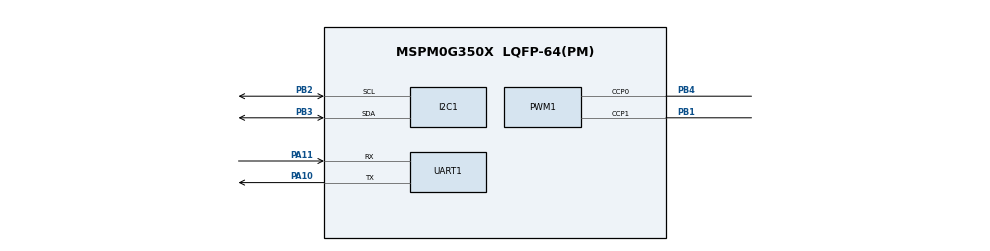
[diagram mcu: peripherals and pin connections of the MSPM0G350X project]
/**
 * @cliArgs --device "MSPM0G350X" --package "LQFP-64(PM)" --part "Default" --product "mspm0_sdk@2.01.00.03"
 * @versions {"tool":"1.20.0+3587"}
 */

/**
 * Import the modules used in this configuration.
 */
const GPIO   = scripting.addModule("/ti/driverlib/GPIO", {}, false);
const GPIO1  = GPIO.addInstance();
const GPIO2  = GPIO.addInstance();
const GPIO3  = GPIO.addInstance();
const GPIO4  = GPIO.addInstance();
const GPIO5  = GPIO.addInstance();
const I2C    = scripting.addModule("/ti/driverlib/I2C", {}, false);
const I2C1   = I2C.addInstance();
const PWM    = scripting.addModule("/ti/driverlib/PWM", {}, false);
const PWM1   = PWM.addInstance();
const SYSCTL = scripting.addModule("/ti/driverlib/SYSCTL");
const TIMER  = scripting.addModule("/ti/driverlib/TIMER", {}, false);
const TIMER1 = TIMER.addInstance();
const UART   = scripting.addModule("/ti/driverlib/UART", {}, false);
const UART1  = UART.addInstance();
const UART2  = UART.addInstance();

/**
 * Write custom configuration values to the imported modules.
 */
const divider6       = system.clockTree["PLL_CLK2X_DIV"];
divider6.divideValue = 4;

const divider7       = system.clockTree["PLL_PDIV"];
divider7.divideValue = 2;

const divider9       = system.clockTree["UDIV"];
divider9.divideValue = 2;

const multiplier2         = system.clockTree["PLL_QDIV"];
multiplier2.multiplyValue = 10;

const mux8       = system.clockTree["HSCLKMUX"];
mux8.inputSelect = "HSCLKMUX_SYSPLL2X";

GPIO1.$name                          = "GRP_RIGHT_AIN";
GPIO1.associatedPins.create(2);
GPIO1.associatedPins[0].assignedPin  = "12";
GPIO1.associatedPins[0].assignedPort = "PORTB";
GPIO1.associatedPins[0].$name        = "RIGHT_AIN1";
GPIO1.associatedPins[1].assignedPort = "PORTB";
GPIO1.associatedPins[1].assignedPin  = "17";
GPIO1.associatedPins[1].$name        = "RIGHT_AIN2";

const Board = scripting.addModule("/ti/driverlib/Board", {}, false);

GPIO2.$name                          = "GRP_LEFT_BIN";
GPIO2.associatedPins.create(2);
GPIO2.associatedPins[0].assignedPort = "PORTA";
GPIO2.associatedPins[0].assignedPin  = "28";
GPIO2.associatedPins[0].$name        = "LEFT_BIN1";
GPIO2.associatedPins[1].assignedPort = "PORTA";
GPIO2.associatedPins[1].assignedPin  = "31";
GPIO2.associatedPins[1].$name        = "LEFT_BIN2";

GPIO3.$name                          = "GRP_ENCODER_RIGHT";
GPIO3.associatedPins.create(2);
GPIO3.associatedPins[0].assignedPort = "PORTB";
GPIO3.associatedPins[0].assignedPin  = "20";
GPIO3.associatedPins[0].direction    = "INPUT";
GPIO3.associatedPins[0].interruptEn  = true;
GPIO3.associatedPins[0].polarity     = "RISE_FALL";
GPIO3.associatedPins[0].$name        = "RIGHT_A";
GPIO3.associatedPins[1].direction    = "INPUT";
GPIO3.associatedPins[1].assignedPort = "PORTB";
GPIO3.associatedPins[1].assignedPin  = "13";
GPIO3.associatedPins[1].$name        = "RIGHT_B";

GPIO4.$name                          = "GRP_ENCODER_LEFT";
GPIO4.associatedPins.create(2);
GPIO4.associatedPins[0].assignedPort = "PORTB";
GPIO4.associatedPins[0].direction    = "INPUT";
GPIO4.associatedPins[0].assignedPin  = "15";
GPIO4.associatedPins[0].interruptEn  = true;
GPIO4.associatedPins[0].polarity     = "RISE_FALL";
GPIO4.associatedPins[0].$name        = "LEFT_A";
GPIO4.associatedPins[1].direction    = "INPUT";
GPIO4.associatedPins[1].assignedPort = "PORTB";
GPIO4.associatedPins[1].assignedPin  = "8";
GPIO4.associatedPins[1].$name        = "LEFT_B";

GPIO5.$name                          = "GPIO_OLED";
GPIO5.associatedPins.create(2);
GPIO5.associatedPins[0].$name        = "PIN_SCL";
GPIO5.associatedPins[0].assignedPort = "PORTA";
GPIO5.associatedPins[0].assignedPin  = "12";
GPIO5.associatedPins[1].$name        = "PIN_SDA";
GPIO5.associatedPins[1].assignedPort = "PORTA";
GPIO5.associatedPins[1].assignedPin  = "13";

I2C1.$name                             = "I2C_MPU6050";
I2C1.basicEnableController             = true;
I2C1.intController                     = ["ARBITRATION_LOST","NACK","RXFIFO_TRIGGER","RX_DONE","TX_DONE"];
I2C1.peripheral.sdaPin.$assign         = "PB3";
I2C1.peripheral.sclPin.$assign         = "PB2";
I2C1.sdaPinConfig.hideOutputInversion  = scripting.forceWrite(false);
I2C1.sdaPinConfig.onlyInternalResistor = scripting.forceWrite(false);
I2C1.sdaPinConfig.passedPeripheralType = scripting.forceWrite("Digital");
I2C1.sdaPinConfig.$name                = "ti_driverlib_gpio_GPIOPinGeneric6";
I2C1.sclPinConfig.hideOutputInversion  = scripting.forceWrite(false);
I2C1.sclPinConfig.onlyInternalResistor = scripting.forceWrite(false);
I2C1.sclPinConfig.passedPeripheralType = scripting.forceWrite("Digital");
I2C1.sclPinConfig.$name                = "ti_driverlib_gpio_GPIOPinGeneric7";

PWM1.timerCount                         = 8000;
PWM1.timerStartTimer                    = true;
PWM1.$name                              = "PWM_Motor";
PWM1.pwmMode                            = "EDGE_ALIGN_UP";
PWM1.peripheral.ccp0Pin.$assign         = "PB4";
PWM1.peripheral.ccp1Pin.$assign         = "PB1";
PWM1.PWM_CHANNEL_0.$name                = "ti_driverlib_pwm_PWMTimerCC0";
PWM1.PWM_CHANNEL_1.$name                = "ti_driverlib_pwm_PWMTimerCC1";
PWM1.ccp0PinConfig.direction            = scripting.forceWrite("OUTPUT");
PWM1.ccp0PinConfig.hideOutputInversion  = scripting.forceWrite(false);
PWM1.ccp0PinConfig.onlyInternalResistor = scripting.forceWrite(false);
PWM1.ccp0PinConfig.passedPeripheralType = scripting.forceWrite("Digital");
PWM1.ccp0PinConfig.$name                = "ti_driverlib_gpio_GPIOPinGeneric0";
PWM1.ccp1PinConfig.direction            = scripting.forceWrite("OUTPUT");
PWM1.ccp1PinConfig.hideOutputInversion  = scripting.forceWrite(false);
PWM1.ccp1PinConfig.onlyInternalResistor = scripting.forceWrite(false);
PWM1.ccp1PinConfig.passedPeripheralType = scripting.forceWrite("Digital");
PWM1.ccp1PinConfig.$name                = "ti_driverlib_gpio_GPIOPinGeneric1";

SYSCTL.forceDefaultClkConfig = true;
SYSCTL.clockTreeEn           = true;

TIMER1.$name              = "TIMER_GLOBAL";
TIMER1.timerPeriod        = "10ms";
TIMER1.timerClkPrescale   = 80;
TIMER1.interrupts         = ["ZERO"];
TIMER1.timerMode          = "PERIODIC_UP";
TIMER1.interruptPriority  = "2";
TIMER1.peripheral.$assign = "TIMG6";

UART1.$name                    = "UART_0";
UART1.targetBaudRate           = 115200;
UART1.enabledInterrupts        = ["RX"];
UART1.peripheral.$assign       = "UART0";
UART1.peripheral.rxPin.$assign = "PA11";
UART1.peripheral.txPin.$assign = "PA10";
UART1.txPinConfig.$name        = "ti_driverlib_gpio_GPIOPinGeneric2";
UART1.rxPinConfig.$name        = "ti_driverlib_gpio_GPIOPinGeneric3";

UART2.$name                            = "UART_BusServo";
UART2.targetBaudRate                   = 115200;
UART2.enabledInterrupts                = ["RX"];
UART2.txPinConfig.direction            = scripting.forceWrite("OUTPUT");
UART2.txPinConfig.hideOutputInversion  = scripting.forceWrite(false);
UART2.txPinConfig.onlyInternalResistor = scripting.forceWrite(false);
UART2.txPinConfig.passedPeripheralType = scripting.forceWrite("Digital");
UART2.txPinConfig.$name                = "ti_driverlib_gpio_GPIOPinGeneric4";
UART2.rxPinConfig.hideOutputInversion  = scripting.forceWrite(false);
UART2.rxPinConfig.onlyInternalResistor = scripting.forceWrite(false);
UART2.rxPinConfig.passedPeripheralType = scripting.forceWrite("Digital");
UART2.rxPinConfig.$name                = "ti_driverlib_gpio_GPIOPinGeneric5";

/**
 * Pinmux solution for unlocked pins/peripherals. This ensures that minor changes to the automatic solver in a future
 * version of the tool will not impact the pinmux you originally saw.  These lines can be completely deleted in order to
 * re-solve from scratch.
 */
GPIO1.associatedPins[0].pin.$suggestSolution = "PB12";
GPIO1.associatedPins[1].pin.$suggestSolution = "PB17";
Board.peripheral.$suggestSolution            = "DEBUGSS";
Board.peripheral.swclkPin.$suggestSolution   = "PA20";
Board.peripheral.swdioPin.$suggestSolution   = "PA19";
GPIO2.associatedPins[0].pin.$suggestSolution = "PA28";
GPIO2.associatedPins[1].pin.$suggestSolution = "PA31";
GPIO3.associatedPins[0].pin.$suggestSolution = "PB20";
GPIO3.associatedPins[1].pin.$suggestSolution = "PB13";
GPIO4.associatedPins[0].pin.$suggestSolution = "PB15";
GPIO4.associatedPins[1].pin.$suggestSolution = "PB8";
GPIO5.associatedPins[0].pin.$suggestSolution = "PA12";
GPIO5.associatedPins[1].pin.$suggestSolution = "PA13";
I2C1.peripheral.$suggestSolution             = "I2C1";
PWM1.peripheral.$suggestSolution             = "TIMA1";
UART2.peripheral.$suggestSolution            = "UART1";
UART2.peripheral.rxPin.$suggestSolution      = "PA18";
UART2.peripheral.txPin.$suggestSolution      = "PA17";
